VERSION ""

NS_ :

BS_:

BU_: CAB500_3C2

BO_ 3221225472 VECTOR__INDEPENDENT_SIG_MSG: 0 Vector__XXX
 SG_ Version : 56|8@1+ (1,0) [0|0] "" Vector__XXX
 SG_ Type : 35|12@0+ (1,0) [0|0] "" Vector__XXX

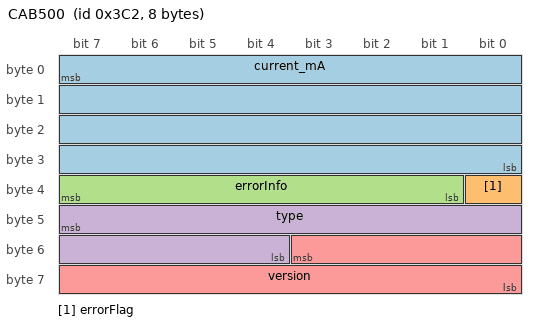
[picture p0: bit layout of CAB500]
BO_ 962 CAB500: 8 CAB500_3C2
 SG_ current_mA : 7|32@0+ (1,2147483648) [-580000|580000] "mA" Vector__XXX
 SG_ errorFlag : 32|1@0+ (1,0) [0|0] "" Vector__XXX
 SG_ errorInfo : 39|7@0+ (1,0) [0|0] "" Vector__XXX
 SG_ type : 47|12@0+ (1,0) [0|0] "" Vector__XXX
 SG_ version : 51|12@0+ (1,0) [0|0] "" Vector__XXX

CM_ BO_ 962 "Current reading, CAB500";
VAL_ 962 errorFlag 0 "noError" 1 "Error" ;
VAL_ 962 errorInfo 64 "Memory Error" 65 "Overcurrent Detection" 66 "Fluxgate no
oscillation\r" 68 "Clock derivation" 70 "Sup. voltage OoR\r" 71 "Hardware default
ADC channel" 73 "New Data not available" 74 "Hardware default
DAC Threshold" 75 "Hardware default
Reference voltage" ;
VAL_ 962 type 3243 "CAB" ;
VAL_ 962 version 1302 "516" ;
